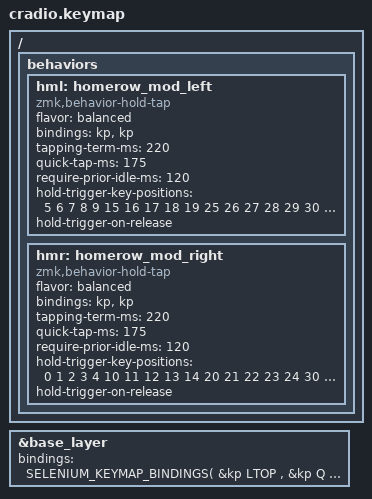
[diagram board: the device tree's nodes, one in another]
// A firmware for a few 34 key keyboards, including Cradio, Hypergolic and Sweep.

#define SELENIUM_KEYMAP_BINDINGS(LOUT1,  LROW1,  RROW1,  ROUT1, \
                                 LOUT2,  LROW2,  RROW2,  ROUT2, \
                                 LOUT3,  LROW3,  RROW3,  ROUT3, \
                                 LT1, LT2, LT3,  RT3, RT2, RT1) \
      LROW1   RROW1 \
      LROW2   RROW2 \
      LROW3   RROW3 \
    LT1 LT2   RT2 RT1

// This keyboard has only two keys per thumb.
// Ensure the 2TK flavor is selected.
#define FOUR_THUMB_KEYS

// Personal: GASC home row mods (pinky → index: Gui, Alt, Shift, Ctrl), mirrored
// on the right hand, same positions on Windows and macOS. Hold-tap tuning carried
// over from ~/src/mwp/zmk-ferris (balanced + opposite-hand triggers), so Shift on
// the middle finger is quick enough for chording.
// Comment out to get Selenium's stock home row mods back.
#define PERSONAL_GASC_HRM

#include <aekeynox/selenium.keymap>

#ifdef PERSONAL_GASC_HRM

/ {
  behaviors {
    hml: homerow_mod_left {
      compatible = "zmk,behavior-hold-tap";
      #binding-cells = <2>;
      flavor = "balanced";
      bindings = <&kp>, <&kp>;
      tapping-term-ms = <220>;
      quick-tap-ms = <175>;
      require-prior-idle-ms = <120>;
      hold-trigger-key-positions = <5 6 7 8 9 15 16 17 18 19 25 26 27 28 29 30 31 32 33>;
      hold-trigger-on-release;
    };
    hmr: homerow_mod_right {
      compatible = "zmk,behavior-hold-tap";
      #binding-cells = <2>;
      flavor = "balanced";
      bindings = <&kp>, <&kp>;
      tapping-term-ms = <220>;
      quick-tap-ms = <175>;
      require-prior-idle-ms = <120>;
      hold-trigger-key-positions = <0 1 2 3 4 10 11 12 13 14 20 21 22 23 24 30 31 32 33>;
      hold-trigger-on-release;
    };
  };
};

// Same as emulations/colemak_dh.dtsi, with GASC home row mods and ' instead of ; top right.
&base_layer {
  bindings = <SELENIUM_KEYMAP_BINDINGS(
    &kp LTOP   ,  &kp Q           &kp W          &kp F            &kp P           &kp B   ,   &kp J  &kp L           &kp U            &kp Y          &kp SQT         ,  &kp RTOP   ,
    &kp LHOME  ,  &hml LGUI A     &hml LALT R    &hml LSHIFT S    &hml LCTRL T    &kp G   ,   &kp M  &hmr RCTRL N    &hmr RSHIFT E    &hmr LALT I    &hmr RGUI O     ,  &kp RHOME  ,
    &kp LSHIFT ,  &kp Z           &kp X          &kp C            &kp D           &kp V   ,   &kp K  &kp H           &kp COMMA        &kp DOT        &kp FSLH        ,  &kp RSHIFT ,
           LTHUMB_TUCK , LTHUMB_HOME , LTHUMB_REACH   ,   RTHUMB_REACH , RTHUMB_HOME , RTHUMB_TUCK
  )>;
};

#endif
